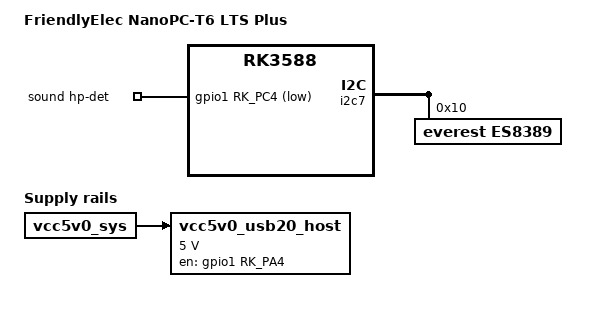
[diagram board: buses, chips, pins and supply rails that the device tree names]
// SPDX-License-Identifier: (GPL-2.0+ OR MIT)
/*
 * Copyright (c) 2021 Rockchip Electronics Co., Ltd.
 * Copyright (c) 2023 Thomas McKahan
 * Copyright (c) 2024 Linaro Ltd.
 * Copyright (c) 2025 FriendlyElec Computer Tech. Co., Ltd.
 * Copyright (c) 2025 Armbian <igor@armbian.com>
 *
 */

/dts-v1/;

#include "rk3588-nanopc-t6.dtsi"

/delete-node/ &rt5616;

/ {
	model = "FriendlyElec NanoPC-T6 LTS Plus";
	compatible = "friendlyarm,nanopc-t6-lts-plus", "rockchip,rk3588";

	/delete-node/ sound;

	sound {
		compatible = "simple-audio-card";
		pinctrl-names = "default";
		pinctrl-0 = <&hp_det>;

		simple-audio-card,name = "everest,es8389-codec";
		simple-audio-card,format = "i2s";
		simple-audio-card,mclk-fs = <256>;

		simple-audio-card,hp-det-gpios = <&gpio1 RK_PC4 GPIO_ACTIVE_LOW>;

		simple-audio-card,widgets =
			"Headphone", "Headphones",
			"Microphone", "Microphone Jack";
		simple-audio-card,routing =
			"Headphones", "HPOL",
			"Headphones", "HPOR",
			"INPUT1", "Microphone Jack",
			"INPUT2", "Microphone Jack";

		simple-audio-card,cpu {
			sound-dai = <&i2s0_8ch>;
		};
		simple-audio-card,codec {
			sound-dai = <&es8389>;
		};
	};

	/* provide power for on-board USB 2.0 hub */
	vcc5v0_usb20_host: regulator-vcc5v0-usb20-host {
		compatible = "regulator-fixed";
		enable-active-high;
		gpio = <&gpio1 RK_PA4 GPIO_ACTIVE_HIGH>;
		pinctrl-0 = <&usb20_host_pwren>;
		pinctrl-names = "default";
		regulator-always-on;
		regulator-boot-on;
		regulator-max-microvolt = <5000000>;
		regulator-min-microvolt = <5000000>;
		regulator-name = "vcc5v0_usb20_host";
		vin-supply = <&vcc5v0_sys>;
	};
};

&i2c7 {
	es8389: audio-codec@10 {
		compatible = "everest,es8389";
		reg = <0x10>;
		assigned-clocks = <&cru I2S0_8CH_MCLKOUT>;
		assigned-clock-rates = <12288000>;
		clocks = <&cru I2S0_8CH_MCLKOUT>;
		clock-names = "mclk";
		#sound-dai-cells = <0>;
	};
};

&i2s0_8ch {
	/delete-node/ port;
};

&pinctrl {
	usb {
		usb20_host_pwren: usb20-host-pwren {
			rockchip,pins = <1 RK_PA4 RK_FUNC_GPIO &pcfg_pull_none>;
		};
	};
};

&u2phy3_host {
	phy-supply = <&vcc5v0_usb20_host>;
};
